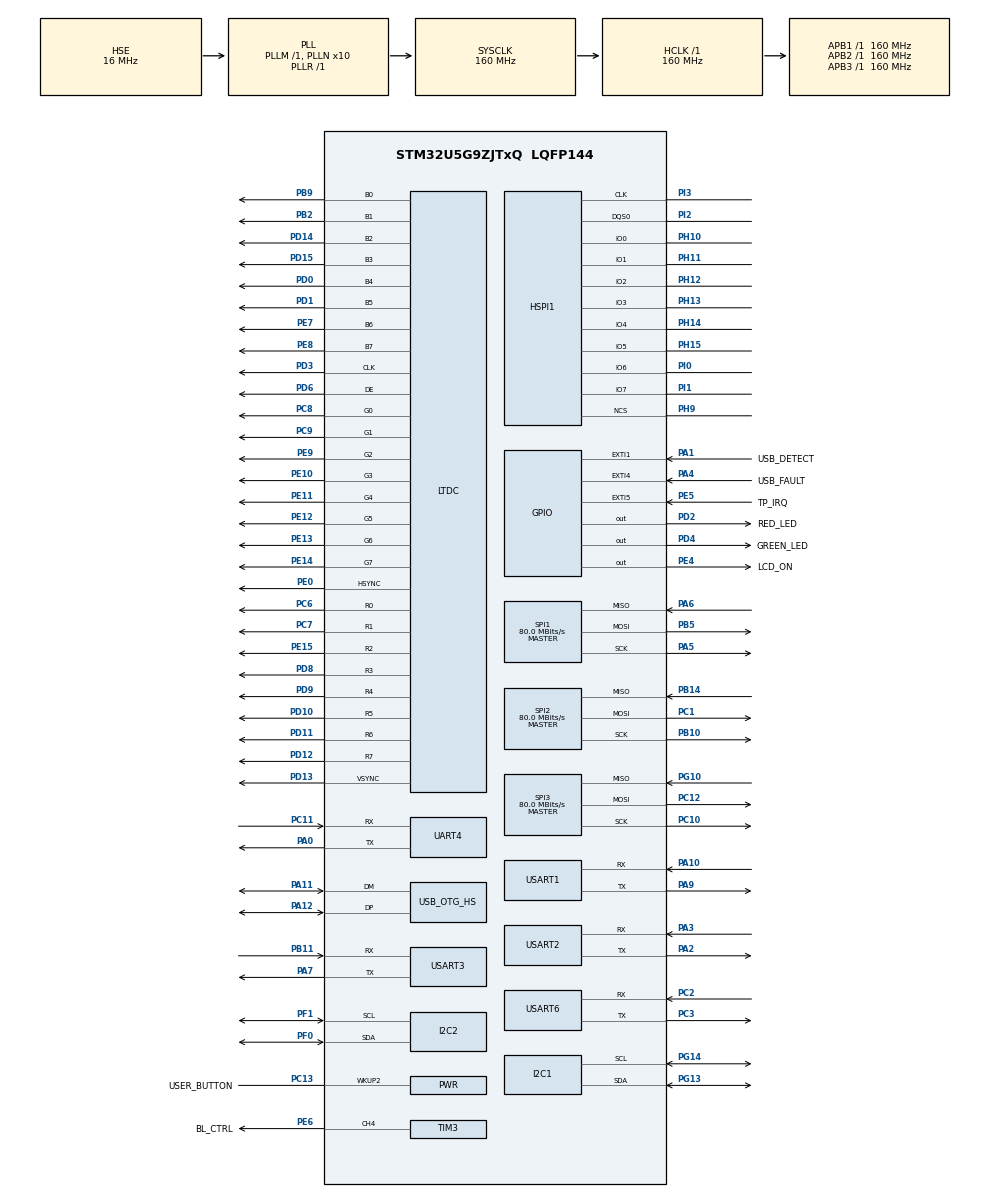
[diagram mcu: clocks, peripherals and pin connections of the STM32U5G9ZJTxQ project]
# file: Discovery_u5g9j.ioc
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ADC1.Channel-0\#ChannelRegularConversion=ADC_CHANNEL_TEMPSENSOR
ADC1.MonitoredBy-0\#ChannelRegularConversion=__NULL
ADC1.NbrOfConversionFlag=1
ADC1.OffsetNumber-0\#ChannelRegularConversion=ADC_OFFSET_NONE
ADC1.Rank-0\#ChannelRegularConversion=1
ADC1.SamplingTime-0\#ChannelRegularConversion=ADC_SAMPLETIME_5CYCLE
ADC1.master=1
CORTEX_M33_NS.userName=CORTEX_M33
DMA2D.ColorMode=DMA2D_OUTPUT_RGB888
DMA2D.Mode=DMA2D_M2M
HSPI1.ChipSelectBoundary=HAL_XSPI_BONDARYOF_NONE
HSPI1.ChipSelectHighTimeCycle=2
HSPI1.FifoThresholdByte=4
HSPI1.MemorySize=HAL_XSPI_SIZE_1GB
HSPI1.MemoryType=HAL_XSPI_MEMTYPE_MACRONIX
I2C1.Timing=0x30909DEC
I2C2.Timing=0x30909DEC
LTDC.ActiveH=480
LTDC.ActiveW=800
LTDC.Alpha_L0=255
LTDC.BlendingFactor1_L0=LTDC_BLENDING_FACTOR1_PAxCA
LTDC.BlendingFactor2_L0=LTDC_BLENDING_FACTOR2_PAxCA
LTDC.HBP=8
LTDC.HFP=8
LTDC.HSync=4
LTDC.Layers=0
LTDC.PCPolarity=LTDC_PCPOLARITY_IPC
LTDC.PixelFormat_L0=LTDC_PIXEL_FORMAT_RGB888
LTDC.VBP=8
LTDC.VFP=8
LTDC.WindowX1_L0=800
LTDC.WindowY1_L0=480
Mcu.Family=STM32U5
Mcu.Name=STM32U5G9ZJTxQ
Mcu.Package=LQFP144
NVIC.EXTI1_IRQn=true\:0\:0\:false\:false\:true\:true\:true\:true
NVIC.EXTI4_IRQn=true\:0\:0\:false\:false\:true\:true\:true\:true
NVIC.EXTI5_IRQn=true\:0\:0\:false\:false\:true\:true\:true\:true
NVIC.I2C2_ER_IRQn=true\:0\:0\:false\:false\:true\:true\:true\:false
NVIC.I2C2_EV_IRQn=true\:0\:0\:false\:false\:true\:true\:true\:true
NVIC.LTDC_IRQn=true\:0\:0\:false\:false\:true\:true\:true\:true
NVIC.PriorityGroup=NVIC_PRIORITYGROUP_4
NVIC.USART1_IRQn=true\:0\:0\:false\:false\:true\:true\:true\:true
PA0.Mode=Asynchronous
PA0.Signal=UART4_TX
PA1.GPIO_Label=USB_DETECT
PA1.GPIO_ModeDefaultEXTI=GPIO_MODE_IT_RISING_FALLING
PA1.Signal=GPXTI1
PA10.Mode=Asynchronous
PA10.Signal=USART1_RX
PA11.Mode=Internal_Phy_Device
PA11.Signal=USB_OTG_HS_DM
PA12.Mode=Internal_Phy_Device
PA12.Signal=USB_OTG_HS_DP
PA13\ (JTMS/SWDIO).Mode=Trace_Asynchronous_SW
PA13\ (JTMS/SWDIO).Signal=DEBUG_JTMS-SWDIO
PA14\ (JTCK/SWCLK).Mode=Trace_Asynchronous_SW
PA14\ (JTCK/SWCLK).Signal=DEBUG_JTCK-SWCLK
PA2.Mode=Asynchronous
PA2.Signal=USART2_TX
PA3.Mode=Asynchronous
PA3.Signal=USART2_RX
PA4.GPIO_Label=USB_FAULT
PA4.GPIO_ModeDefaultEXTI=GPIO_MODE_IT_FALLING
PA4.GPIO_PuPd=GPIO_PULLUP
PA4.Signal=GPXTI4
PA5.Mode=Full_Duplex_Master
PA5.Signal=SPI1_SCK
PA6.Mode=Full_Duplex_Master
PA6.Signal=SPI1_MISO
PA7.Mode=Asynchronous
PA7.Signal=USART3_TX
PA9.Mode=Asynchronous
PA9.Signal=USART1_TX
PB10.Mode=Full_Duplex_Master
PB10.Signal=SPI2_SCK
PB11.Mode=Asynchronous
PB11.Signal=USART3_RX
PB14.Mode=Full_Duplex_Master
PB14.Signal=SPI2_MISO
PB2.Mode=RGB888
PB2.Signal=LTDC_B1
PB3\ (JTDO/TRACESWO).Mode=Trace_Asynchronous_SW
PB3\ (JTDO/TRACESWO).Signal=DEBUG_JTDO-SWO
PB5.Mode=Full_Duplex_Master
PB5.Signal=SPI1_MOSI
PB9.Mode=RGB888
PB9.Signal=LTDC_B0
PC1.Mode=Full_Duplex_Master
PC1.Signal=SPI2_MOSI
PC10.Mode=Full_Duplex_Master
PC10.Signal=SPI3_SCK
PC11.Mode=Asynchronous
PC11.Signal=UART4_RX
PC12.Mode=Full_Duplex_Master
PC12.Signal=SPI3_MOSI
PC13.GPIO_Label=USER_BUTTON
PC13.Mode=WakeUp2
PC13.Signal=PWR_WKUP2
PC14-OSC32_IN\ (PC14).Mode=LSE-External-Oscillator
PC14-OSC32_IN\ (PC14).Signal=RCC_OSC32_IN
PC15-OSC32_OUT\ (PC15).Mode=LSE-External-Oscillator
PC15-OSC32_OUT\ (PC15).Signal=RCC_OSC32_OUT
PC2.Mode=Asynchronous
PC2.Signal=USART6_RX
PC3.Mode=Asynchronous
PC3.Signal=USART6_TX
PC6.Mode=RGB888
PC6.Signal=LTDC_R0
PC7.Mode=RGB888
PC7.Signal=LTDC_R1
PC8.Mode=RGB888
PC8.Signal=LTDC_G0
PC9.Mode=RGB888
PC9.Signal=LTDC_G1
PD0.Mode=RGB888
PD0.Signal=LTDC_B4
PD1.Mode=RGB888
PD1.Signal=LTDC_B5
PD10.Mode=RGB888
PD10.Signal=LTDC_R5
PD11.Mode=RGB888
PD11.Signal=LTDC_R6
PD12.Mode=RGB888
PD12.Signal=LTDC_R7
PD13.Mode=RGB888
PD13.Signal=LTDC_VSYNC
PD14.Mode=RGB888
PD14.Signal=LTDC_B2
PD15.Mode=RGB888
PD15.Signal=LTDC_B3
PD2.GPIO_Label=RED_LED
PD2.Signal=GPIO_Output
PD3.Mode=RGB888
PD3.Signal=LTDC_CLK
PD4.GPIO_Label=GREEN_LED
PD4.Signal=GPIO_Output
PD6.Mode=RGB888
PD6.Signal=LTDC_DE
PD8.Mode=RGB888
PD8.Signal=LTDC_R3
PD9.Mode=RGB888
PD9.Signal=LTDC_R4
PE0.Mode=RGB888
PE0.Signal=LTDC_HSYNC
PE10.Mode=RGB888
PE10.Signal=LTDC_G3
PE11.Mode=RGB888
PE11.Signal=LTDC_G4
PE12.Mode=RGB888
PE12.Signal=LTDC_G5
PE13.Mode=RGB888
PE13.Signal=LTDC_G6
PE14.Mode=RGB888
PE14.Signal=LTDC_G7
PE15.Mode=RGB888
PE15.Signal=LTDC_R2
PE4.GPIO_Label=LCD_ON
PE4.PinState=GPIO_PIN_SET
PE4.Signal=GPIO_Output
PE5.GPIO_Label=TP_IRQ
PE5.Signal=GPXTI5
PE6.GPIO_Label=BL_CTRL
PE6.Signal=S_TIM3_CH4
PE7.Mode=RGB888
PE7.Signal=LTDC_B6
PE8.Mode=RGB888
PE8.Signal=LTDC_B7
PE9.Mode=RGB888
PE9.Signal=LTDC_G2
PF0.Mode=I2C
PF0.Signal=I2C2_SDA
PF1.Mode=I2C
PF1.Signal=I2C2_SCL
PG10.Mode=Full_Duplex_Master
PG10.Signal=SPI3_MISO
PG13.Mode=I2C
PG13.Signal=I2C1_SDA
PG14.Mode=I2C
PG14.Signal=I2C1_SCL
PH0-OSC_IN\ (PH0).Mode=HSE-External-Oscillator
PH0-OSC_IN\ (PH0).Signal=RCC_OSC_IN
PH1-OSC_OUT\ (PH1).Mode=HSE-External-Oscillator
PH1-OSC_OUT\ (PH1).Signal=RCC_OSC_OUT
PH10.Mode=octo_mode
PH10.Signal=HSPI1_IO0
PH11.Mode=octo_mode
PH11.Signal=HSPI1_IO1
PH12.Mode=octo_mode
PH12.Signal=HSPI1_IO2
PH13.Mode=octo_mode
PH13.Signal=HSPI1_IO3
PH14.Mode=octo_mode
PH14.Signal=HSPI1_IO4
PH15.Mode=octo_mode
PH15.Signal=HSPI1_IO5
PH9.Mode=octo_mode
PH9.Signal=HSPI1_NCS
PI0.Mode=octo_mode
PI0.Signal=HSPI1_IO6
PI1.Mode=octo_mode
PI1.Signal=HSPI1_IO7
PI2.Mode=octo_mode
PI2.Signal=HSPI1_DQS0
PI3.Mode=octo_mode
PI3.Signal=HSPI1_CLK
PWR.PowerMode=PWR_SMPS_SUPPLY
ProjectManager.HeapSize=0x200
ProjectManager.StackSize=0x400
ProjectManager.TargetToolchain=STM32CubeIDE
RCC.ADCFreq_Value=16000000
RCC.AHBFreq_Value=160000000
RCC.APB1Freq_Value=160000000
RCC.APB1TimFreq_Value=160000000
RCC.APB2Freq_Value=160000000
RCC.APB2TimFreq_Value=160000000
RCC.APB3Freq_Value=160000000
RCC.CortexFreq_Value=160000000
RCC.EPOD_VALUE=16000000
RCC.HCLKFreq_Value=160000000
RCC.HSE_VALUE=16000000
RCC.HSI48_VALUE=48000000
RCC.HSI_VALUE=16000000
RCC.HSPICLockSelection=RCC_HSPICLKSOURCE_PLL2
RCC.LSIDIV_VALUE=32000
RCC.LTDCCLockSelection=RCC_LTDCCLKSOURCE_PLL3
RCC.MSIClockRange=RCC_MSIRANGE_0
RCC.MSI_VALUE=48000000
RCC.PLL1P=8
RCC.PLL1R=1
RCC.PLL2FRACN=0
RCC.PLL2N=25
RCC.PLL2Q=3
RCC.PLL2R=4
RCC.PLL2Source=RCC_PLLSOURCE_HSE
RCC.PLL3FRACN=0
RCC.PLL3M=4
RCC.PLL3N=50
RCC.PLL3R=8
RCC.PLL3Source=RCC_PLLSOURCE_HSE
RCC.PLLFRACN=0
RCC.PLLN=10
RCC.RTCClockSelection=RCC_RTCCLKSOURCE_LSE
RCC.SYSCLKFreq_VALUE=160000000
RCC.SYSCLKSource=RCC_SYSCLKSOURCE_PLLCLK
RCC.VCOOutputFreq_Value=160000000
SH.S_TIM3_CH4.0=TIM3_CH4,PWM Generation4 CH4
SPI1.CalculateBaudRate=80.0 MBits/s
SPI1.Direction=SPI_DIRECTION_2LINES
SPI1.Mode=SPI_MODE_MASTER
SPI1.VirtualType=VM_MASTER
SPI2.CalculateBaudRate=80.0 MBits/s
SPI2.Direction=SPI_DIRECTION_2LINES
SPI2.Mode=SPI_MODE_MASTER
SPI2.VirtualType=VM_MASTER
SPI3.CalculateBaudRate=80.0 MBits/s
SPI3.Direction=SPI_DIRECTION_2LINES
SPI3.Mode=SPI_MODE_MASTER
SPI3.VirtualType=VM_MASTER
TIM3.Channel-PWM\ Generation4\ CH4=TIM_CHANNEL_4
TIM3.OC4Preload_PWM=DISABLE
TIM3.PeriodNoDither=100
TIM3.Prescaler=160
TIM3.PulseNoDither_4=75
USART1.VirtualMode-Asynchronous=VM_ASYNC
USART2.VirtualMode-Asynchronous=VM_ASYNC
USART3.VirtualMode-Asynchronous=VM_ASYNC
USART6.VirtualMode-Asynchronous=VM_ASYNC
USB_OTG_HS.VirtualMode=Device_HS
VP_ADC1_TempSens_Input.Mode=IN-TempSens
VP_DMA2D_VS_DMA2D.Mode=DMA2D_Activate
VP_ICACHE_VS_ICACHE.Mode=DirectMappedCache
VP_LPBAMQUEUE_VS_QUEUE.Mode=QUEUEMODE
VP_MEMORYMAP_VS_MEMORYMAP.Mode=CurAppReg
VP_PWR_VS_LPOM.Mode=PowerOptimisation
VP_PWR_VS_SECSignals.Mode=Security/Privilege
VP_PWR_Vdda.Mode=isolationVdda
VP_RTC_VS_RTC_Activate.Mode=RTC_Enabled
board=STM32U5G9J-DK2

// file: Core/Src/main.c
/* USER CODE BEGIN Header */
/**
  ******************************************************************************
  * @file           : main.c
  * @brief          : Main program body
  ******************************************************************************
  * @attention
  *
  * Copyright (c) 2026 STMicroelectronics.
  * All rights reserved.
  *
  * This software is licensed under terms that can be found in the LICENSE file
  * in the root directory of this software component.
  * If no LICENSE file comes with this software, it is provided AS-IS.
  *
  ******************************************************************************
  */
/* USER CODE END Header */
#include "main.h"
#include "FreeRTOS.h"   /* V6/A1.5: el kernel */
#include "task.h"

/* USER CODE BEGIN Includes */
#include "stm32_repl.h"
/* USER CODE END Includes */

ADC_HandleTypeDef hadc1;

DMA2D_HandleTypeDef hdma2d;

XSPI_HandleTypeDef hxspi1;

I2C_HandleTypeDef hi2c1;
I2C_HandleTypeDef hi2c2;

LTDC_HandleTypeDef hltdc;

RTC_HandleTypeDef hrtc;

SPI_HandleTypeDef hspi1;
SPI_HandleTypeDef hspi2;
SPI_HandleTypeDef hspi3;

TIM_HandleTypeDef htim3;

UART_HandleTypeDef huart4;
UART_HandleTypeDef huart1;
UART_HandleTypeDef huart2;
UART_HandleTypeDef huart3;
UART_HandleTypeDef huart6;

PCD_HandleTypeDef hpcd_USB_OTG_HS;

void SystemClock_Config(void);
static void SystemPower_Config(void);
static void MX_GPIO_Init(void);
static void MX_DMA2D_Init(void);
static void MX_HSPI1_Init(void);
static void MX_I2C1_Init(void);
static void MX_I2C2_Init(void);
static void MX_ICACHE_Init(void);
static void MX_LTDC_Init(void);
static void MX_RTC_Init(void);
static void MX_SPI1_Init(void);
static void MX_SPI2_Init(void);
static void MX_SPI3_Init(void);
static void MX_TIM3_Init(void);
static void MX_UART4_Init(void);
static void MX_USART1_UART_Init(void);
static void MX_USART2_UART_Init(void);
static void MX_USART3_UART_Init(void);
static void MX_USART6_UART_Init(void);
static void MX_USB_OTG_HS_PCD_Init(void);
static void MX_ADC1_Init(void);

/* V6/A1.5 - la tarea `vm`: lo de siempre, sobre su pila y bajo el planificador. */
static void vm_task(void* arg)
{
  (void) arg;
  for (;;) { stm32_repl_run(); }
}

int main(void)
{

  /* MCU Configuration--------------------------------------------------------*/

  /* Reset of all peripherals, Initializes the Flash interface and the Systick. */
  HAL_Init();

  /* Configure the System Power */
  SystemPower_Config();

  /* Configure the system clock */
  SystemClock_Config();

  /* Initialize all configured peripherals */
  MX_GPIO_Init();
  MX_DMA2D_Init();
  MX_HSPI1_Init();
  MX_I2C1_Init();
  MX_I2C2_Init();
  MX_ICACHE_Init();
  MX_LTDC_Init();
  MX_RTC_Init();
  MX_SPI1_Init();
  MX_SPI2_Init();
  MX_SPI3_Init();
  MX_TIM3_Init();
  MX_UART4_Init();
  MX_USART1_UART_Init();
  MX_USART2_UART_Init();
  MX_USART3_UART_Init();
  MX_USART6_UART_Init();
  MX_USB_OTG_HS_PCD_Init();
  MX_ADC1_Init();

  /* Infinite loop */
  /* USER CODE BEGIN WHILE */
  /* V6/A1.5 - LAS DOS TAREAS (ver el gemelo en Nucleo_u575b/Core/Src/main.c).
   * La pila de `vm`, 4096 PALABRAS = 16 KB: el mismo _Min_Stack_Size que el
   * enlazador reservaba como MSP para que el interprete corriera encima. */
  if (xTaskCreate(vm_task, "vm", 4096, NULL, tskIDLE_PRIORITY + 2, NULL) != pdPASS) {
    Error_Handler();
  }
  vTaskStartScheduler();
  Error_Handler();   /* solo se llega aqui si el planificador no arranco */
  while (1) { }
  /* USER CODE END 3 */
}

void SystemClock_Config(void)
{
  RCC_OscInitTypeDef RCC_OscInitStruct = {0};
  RCC_ClkInitTypeDef RCC_ClkInitStruct = {0};

  /** Configure the main internal regulator output voltage
  */
  if (HAL_PWREx_ControlVoltageScaling(PWR_REGULATOR_VOLTAGE_SCALE1) != HAL_OK)
  {
    Error_Handler();
  }

  /** Configure LSE Drive Capability
  */
  HAL_PWR_EnableBkUpAccess();
  __HAL_RCC_LSEDRIVE_CONFIG(RCC_LSEDRIVE_LOW);

  /** Initializes the CPU, AHB and APB buses clocks
  */
  RCC_OscInitStruct.OscillatorType = RCC_OSCILLATORTYPE_HSI|RCC_OSCILLATORTYPE_HSE
                              |RCC_OSCILLATORTYPE_LSE|RCC_OSCILLATORTYPE_MSI;
  RCC_OscInitStruct.HSEState = RCC_HSE_ON;
  RCC_OscInitStruct.LSEState = RCC_LSE_ON;
  RCC_OscInitStruct.HSIState = RCC_HSI_ON;
  RCC_OscInitStruct.HSICalibrationValue = RCC_HSICALIBRATION_DEFAULT;
  RCC_OscInitStruct.MSIState = RCC_MSI_ON;
  RCC_OscInitStruct.MSICalibrationValue = RCC_MSICALIBRATION_DEFAULT;
  RCC_OscInitStruct.MSIClockRange = RCC_MSIRANGE_0;
  RCC_OscInitStruct.PLL.PLLState = RCC_PLL_ON;
  RCC_OscInitStruct.PLL.PLLSource = RCC_PLLSOURCE_HSE;
  RCC_OscInitStruct.PLL.PLLMBOOST = RCC_PLLMBOOST_DIV1;
  RCC_OscInitStruct.PLL.PLLM = 1;
  RCC_OscInitStruct.PLL.PLLN = 10;
  RCC_OscInitStruct.PLL.PLLP = 8;
  RCC_OscInitStruct.PLL.PLLQ = 2;
  RCC_OscInitStruct.PLL.PLLR = 1;
  RCC_OscInitStruct.PLL.PLLRGE = RCC_PLLVCIRANGE_1;
  RCC_OscInitStruct.PLL.PLLFRACN = 0;
  if (HAL_RCC_OscConfig(&RCC_OscInitStruct) != HAL_OK)
  {
    Error_Handler();
  }

  /** Initializes the CPU, AHB and APB buses clocks
  */
  RCC_ClkInitStruct.ClockType = RCC_CLOCKTYPE_HCLK|RCC_CLOCKTYPE_SYSCLK
                              |RCC_CLOCKTYPE_PCLK1|RCC_CLOCKTYPE_PCLK2
                              |RCC_CLOCKTYPE_PCLK3;
  RCC_ClkInitStruct.SYSCLKSource = RCC_SYSCLKSOURCE_PLLCLK;
  RCC_ClkInitStruct.AHBCLKDivider = RCC_SYSCLK_DIV1;
  RCC_ClkInitStruct.APB1CLKDivider = RCC_HCLK_DIV1;
  RCC_ClkInitStruct.APB2CLKDivider = RCC_HCLK_DIV1;
  RCC_ClkInitStruct.APB3CLKDivider = RCC_HCLK_DIV1;

  if (HAL_RCC_ClockConfig(&RCC_ClkInitStruct, FLASH_LATENCY_4) != HAL_OK)
  {
    Error_Handler();
  }
}

/**
  * @brief Power Configuration
  * @retval None
  */
static void SystemPower_Config(void)
{
  HAL_PWREx_EnableVddIO2();

  /*
   * Switch to SMPS regulator instead of LDO
   */
  if (HAL_PWREx_ConfigSupply(PWR_SMPS_SUPPLY) != HAL_OK)
  {
    Error_Handler();
  }
}

static void MX_ADC1_Init(void)
{

  ADC_ChannelConfTypeDef sConfig = {0};

  /** Common config
  */
  hadc1.Instance = ADC1;
  hadc1.Init.ClockPrescaler = ADC_CLOCK_ASYNC_DIV1;
  hadc1.Init.Resolution = ADC_RESOLUTION_14B;
  hadc1.Init.GainCompensation = 0;
  hadc1.Init.DataAlign = ADC_DATAALIGN_RIGHT;
  hadc1.Init.ScanConvMode = ADC_SCAN_DISABLE;
  hadc1.Init.EOCSelection = ADC_EOC_SINGLE_CONV;
  hadc1.Init.LowPowerAutoWait = DISABLE;
  hadc1.Init.ContinuousConvMode = DISABLE;
  hadc1.Init.NbrOfConversion = 1;
  hadc1.Init.DiscontinuousConvMode = DISABLE;
  hadc1.Init.ExternalTrigConv = ADC_SOFTWARE_START;
  hadc1.Init.ExternalTrigConvEdge = ADC_EXTERNALTRIGCONVEDGE_NONE;
  hadc1.Init.DMAContinuousRequests = DISABLE;
  hadc1.Init.TriggerFrequencyMode = ADC_TRIGGER_FREQ_HIGH;
  hadc1.Init.Overrun = ADC_OVR_DATA_PRESERVED;
  hadc1.Init.LeftBitShift = ADC_LEFTBITSHIFT_NONE;
  hadc1.Init.ConversionDataManagement = ADC_CONVERSIONDATA_DR;
  hadc1.Init.OversamplingMode = DISABLE;
  if (HAL_ADC_Init(&hadc1) != HAL_OK)
  {
    Error_Handler();
  }

  /** Configure Regular Channel
  */
  sConfig.Channel = ADC_CHANNEL_TEMPSENSOR;
  sConfig.Rank = ADC_REGULAR_RANK_1;
  sConfig.SamplingTime = ADC_SAMPLETIME_5CYCLE;
  sConfig.SingleDiff = ADC_SINGLE_ENDED;
  sConfig.OffsetNumber = ADC_OFFSET_NONE;
  sConfig.Offset = 0;
  if (HAL_ADC_ConfigChannel(&hadc1, &sConfig) != HAL_OK)
  {
    Error_Handler();
  }

}

static void MX_DMA2D_Init(void)
{

  hdma2d.Instance = DMA2D;
  hdma2d.Init.Mode = DMA2D_M2M;
  hdma2d.Init.ColorMode = DMA2D_OUTPUT_RGB888;
  hdma2d.Init.OutputOffset = 0;
  hdma2d.Init.BytesSwap = DMA2D_BYTES_REGULAR;
  hdma2d.Init.LineOffsetMode = DMA2D_LOM_PIXELS;
  hdma2d.LayerCfg[1].InputOffset = 0;
  hdma2d.LayerCfg[1].InputColorMode = DMA2D_INPUT_RGB888;
  hdma2d.LayerCfg[1].AlphaMode = DMA2D_NO_MODIF_ALPHA;
  hdma2d.LayerCfg[1].InputAlpha = 0;
  hdma2d.LayerCfg[1].AlphaInverted = DMA2D_REGULAR_ALPHA;
  hdma2d.LayerCfg[1].RedBlueSwap = DMA2D_RB_REGULAR;
  if (HAL_DMA2D_Init(&hdma2d) != HAL_OK)
  {
    Error_Handler();
  }
  if (HAL_DMA2D_ConfigLayer(&hdma2d, 1) != HAL_OK)
  {
    Error_Handler();
  }

}

static void MX_HSPI1_Init(void)
{

  /* HSPI1 parameter configuration*/
  hxspi1.Instance = HSPI1;
  hxspi1.Init.FifoThresholdByte = 4;
  hxspi1.Init.MemoryMode = HAL_XSPI_SINGLE_MEM;
  hxspi1.Init.MemoryType = HAL_XSPI_MEMTYPE_MACRONIX;
  hxspi1.Init.MemorySize = HAL_XSPI_SIZE_1GB;
  hxspi1.Init.ChipSelectHighTimeCycle = 2;
  hxspi1.Init.FreeRunningClock = HAL_XSPI_FREERUNCLK_DISABLE;
  hxspi1.Init.ClockMode = HAL_XSPI_CLOCK_MODE_0;
  hxspi1.Init.WrapSize = HAL_XSPI_WRAP_NOT_SUPPORTED;
  hxspi1.Init.ClockPrescaler = 0;
  hxspi1.Init.SampleShifting = HAL_XSPI_SAMPLE_SHIFT_NONE;
  hxspi1.Init.DelayHoldQuarterCycle = HAL_XSPI_DHQC_DISABLE;
  hxspi1.Init.ChipSelectBoundary = HAL_XSPI_BONDARYOF_NONE;
  hxspi1.Init.MaxTran = 0;
  hxspi1.Init.Refresh = 0;
  if (HAL_XSPI_Init(&hxspi1) != HAL_OK)
  {
    Error_Handler();
  }

}

static void MX_I2C1_Init(void)
{

  hi2c1.Instance = I2C1;
  hi2c1.Init.Timing = 0x30909DEC;
  hi2c1.Init.OwnAddress1 = 0;
  hi2c1.Init.AddressingMode = I2C_ADDRESSINGMODE_7BIT;
  hi2c1.Init.DualAddressMode = I2C_DUALADDRESS_DISABLE;
  hi2c1.Init.OwnAddress2 = 0;
  hi2c1.Init.OwnAddress2Masks = I2C_OA2_NOMASK;
  hi2c1.Init.GeneralCallMode = I2C_GENERALCALL_DISABLE;
  hi2c1.Init.NoStretchMode = I2C_NOSTRETCH_DISABLE;
  if (HAL_I2C_Init(&hi2c1) != HAL_OK)
  {
    Error_Handler();
  }

  /** Configure Analogue filter
  */
  if (HAL_I2CEx_ConfigAnalogFilter(&hi2c1, I2C_ANALOGFILTER_ENABLE) != HAL_OK)
  {
    Error_Handler();
  }

  /** Configure Digital filter
  */
  if (HAL_I2CEx_ConfigDigitalFilter(&hi2c1, 0) != HAL_OK)
  {
    Error_Handler();
  }

}

static void MX_I2C2_Init(void)
{

  hi2c2.Instance = I2C2;
  hi2c2.Init.Timing = 0x30909DEC;
  hi2c2.Init.OwnAddress1 = 0;
  hi2c2.Init.AddressingMode = I2C_ADDRESSINGMODE_7BIT;
  hi2c2.Init.DualAddressMode = I2C_DUALADDRESS_DISABLE;
  hi2c2.Init.OwnAddress2 = 0;
  hi2c2.Init.OwnAddress2Masks = I2C_OA2_NOMASK;
  hi2c2.Init.GeneralCallMode = I2C_GENERALCALL_DISABLE;
  hi2c2.Init.NoStretchMode = I2C_NOSTRETCH_DISABLE;
  if (HAL_I2C_Init(&hi2c2) != HAL_OK)
  {
    Error_Handler();
  }

  /** Configure Analogue filter
  */
  if (HAL_I2CEx_ConfigAnalogFilter(&hi2c2, I2C_ANALOGFILTER_ENABLE) != HAL_OK)
  {
    Error_Handler();
  }

  /** Configure Digital filter
  */
  if (HAL_I2CEx_ConfigDigitalFilter(&hi2c2, 0) != HAL_OK)
  {
    Error_Handler();
  }

}

static void MX_ICACHE_Init(void)
{

  /** Enable instruction cache in 1-way (direct mapped cache)
  */
  if (HAL_ICACHE_ConfigAssociativityMode(ICACHE_1WAY) != HAL_OK)
  {
    Error_Handler();
  }
  if (HAL_ICACHE_Enable() != HAL_OK)
  {
    Error_Handler();
  }

}

static void MX_LTDC_Init(void)
{

  LTDC_LayerCfgTypeDef pLayerCfg = {0};

  hltdc.Instance = LTDC;
  hltdc.Init.HSPolarity = LTDC_HSPOLARITY_AL;
  hltdc.Init.VSPolarity = LTDC_VSPOLARITY_AL;
  hltdc.Init.DEPolarity = LTDC_DEPOLARITY_AL;
  hltdc.Init.PCPolarity = LTDC_PCPOLARITY_IPC;
  hltdc.Init.HorizontalSync = 3;
  hltdc.Init.VerticalSync = 3;
  hltdc.Init.AccumulatedHBP = 11;
  hltdc.Init.AccumulatedVBP = 11;
  hltdc.Init.AccumulatedActiveW = 811;
  hltdc.Init.AccumulatedActiveH = 491;
  hltdc.Init.TotalWidth = 819;
  hltdc.Init.TotalHeigh = 499;
  hltdc.Init.Backcolor.Blue = 0;
  hltdc.Init.Backcolor.Green = 0;
  hltdc.Init.Backcolor.Red = 0;
  if (HAL_LTDC_Init(&hltdc) != HAL_OK)
  {
    Error_Handler();
  }
  pLayerCfg.WindowX0 = 0;
  pLayerCfg.WindowX1 = 800;
  pLayerCfg.WindowY0 = 0;
  pLayerCfg.WindowY1 = 480;
  pLayerCfg.PixelFormat = LTDC_PIXEL_FORMAT_RGB888;
  pLayerCfg.Alpha = 255;
  pLayerCfg.Alpha0 = 0;
  pLayerCfg.BlendingFactor1 = LTDC_BLENDING_FACTOR1_PAxCA;
  pLayerCfg.BlendingFactor2 = LTDC_BLENDING_FACTOR2_PAxCA;
  pLayerCfg.FBStartAdress = 0;
  pLayerCfg.ImageWidth = 0;
  pLayerCfg.ImageHeight = 0;
  pLayerCfg.Backcolor.Blue = 0;
  pLayerCfg.Backcolor.Green = 0;
  pLayerCfg.Backcolor.Red = 0;
  if (HAL_LTDC_ConfigLayer(&hltdc, &pLayerCfg, 0) != HAL_OK)
  {
    Error_Handler();
  }

}

static void MX_RTC_Init(void)
{

  RTC_PrivilegeStateTypeDef privilegeState = {0};

  /** Initialize RTC Only
  */
  hrtc.Instance = RTC;
  hrtc.Init.HourFormat = RTC_HOURFORMAT_24;
  hrtc.Init.AsynchPrediv = 127;
  hrtc.Init.SynchPrediv = 255;
  hrtc.Init.OutPut = RTC_OUTPUT_DISABLE;
  hrtc.Init.OutPutRemap = RTC_OUTPUT_REMAP_NONE;
  hrtc.Init.OutPutPolarity = RTC_OUTPUT_POLARITY_HIGH;
  hrtc.Init.OutPutType = RTC_OUTPUT_TYPE_OPENDRAIN;
  hrtc.Init.OutPutPullUp = RTC_OUTPUT_PULLUP_NONE;
  hrtc.Init.BinMode = RTC_BINARY_NONE;
  if (HAL_RTC_Init(&hrtc) != HAL_OK)
  {
    Error_Handler();
  }
  privilegeState.rtcPrivilegeFull = RTC_PRIVILEGE_FULL_NO;
  privilegeState.backupRegisterPrivZone = RTC_PRIVILEGE_BKUP_ZONE_NONE;
  privilegeState.backupRegisterStartZone2 = RTC_BKP_DR0;
  privilegeState.backupRegisterStartZone3 = RTC_BKP_DR0;
  if (HAL_RTCEx_PrivilegeModeSet(&hrtc, &privilegeState) != HAL_OK)
  {
    Error_Handler();
  }

}

static void MX_SPI1_Init(void)
{

  SPI_AutonomousModeConfTypeDef HAL_SPI_AutonomousMode_Cfg_Struct = {0};

  /* SPI1 parameter configuration*/
  hspi1.Instance = SPI1;
  hspi1.Init.Mode = SPI_MODE_MASTER;
  hspi1.Init.Direction = SPI_DIRECTION_2LINES;
  hspi1.Init.DataSize = SPI_DATASIZE_4BIT;
  hspi1.Init.CLKPolarity = SPI_POLARITY_LOW;
  hspi1.Init.CLKPhase = SPI_PHASE_1EDGE;
  hspi1.Init.NSS = SPI_NSS_SOFT;
  hspi1.Init.BaudRatePrescaler = SPI_BAUDRATEPRESCALER_2;
  hspi1.Init.FirstBit = SPI_FIRSTBIT_MSB;
  hspi1.Init.TIMode = SPI_TIMODE_DISABLE;
  hspi1.Init.CRCCalculation = SPI_CRCCALCULATION_DISABLE;
  hspi1.Init.CRCPolynomial = 0x7;
  hspi1.Init.NSSPMode = SPI_NSS_PULSE_ENABLE;
  hspi1.Init.NSSPolarity = SPI_NSS_POLARITY_LOW;
  hspi1.Init.FifoThreshold = SPI_FIFO_THRESHOLD_01DATA;
  hspi1.Init.MasterSSIdleness = SPI_MASTER_SS_IDLENESS_00CYCLE;
  hspi1.Init.MasterInterDataIdleness = SPI_MASTER_INTERDATA_IDLENESS_00CYCLE;
  hspi1.Init.MasterReceiverAutoSusp = SPI_MASTER_RX_AUTOSUSP_DISABLE;
  hspi1.Init.MasterKeepIOState = SPI_MASTER_KEEP_IO_STATE_DISABLE;
  hspi1.Init.IOSwap = SPI_IO_SWAP_DISABLE;
  hspi1.Init.ReadyMasterManagement = SPI_RDY_MASTER_MANAGEMENT_INTERNALLY;
  hspi1.Init.ReadyPolarity = SPI_RDY_POLARITY_HIGH;
  if (HAL_SPI_Init(&hspi1) != HAL_OK)
  {
    Error_Handler();
  }
  HAL_SPI_AutonomousMode_Cfg_Struct.TriggerState = SPI_AUTO_MODE_DISABLE;
  HAL_SPI_AutonomousMode_Cfg_Struct.TriggerSelection = SPI_GRP1_GPDMA_CH0_TCF_TRG;
  HAL_SPI_AutonomousMode_Cfg_Struct.TriggerPolarity = SPI_TRIG_POLARITY_RISING;
  if (HAL_SPIEx_SetConfigAutonomousMode(&hspi1, &HAL_SPI_AutonomousMode_Cfg_Struct) != HAL_OK)
  {
    Error_Handler();
  }

}

static void MX_SPI2_Init(void)
{

  SPI_AutonomousModeConfTypeDef HAL_SPI_AutonomousMode_Cfg_Struct = {0};

  /* SPI2 parameter configuration*/
  hspi2.Instance = SPI2;
  hspi2.Init.Mode = SPI_MODE_MASTER;
  hspi2.Init.Direction = SPI_DIRECTION_2LINES;
  hspi2.Init.DataSize = SPI_DATASIZE_4BIT;
  hspi2.Init.CLKPolarity = SPI_POLARITY_LOW;
  hspi2.Init.CLKPhase = SPI_PHASE_1EDGE;
  hspi2.Init.NSS = SPI_NSS_SOFT;
  hspi2.Init.BaudRatePrescaler = SPI_BAUDRATEPRESCALER_2;
  hspi2.Init.FirstBit = SPI_FIRSTBIT_MSB;
  hspi2.Init.TIMode = SPI_TIMODE_DISABLE;
  hspi2.Init.CRCCalculation = SPI_CRCCALCULATION_DISABLE;
  hspi2.Init.CRCPolynomial = 0x7;
  hspi2.Init.NSSPMode = SPI_NSS_PULSE_ENABLE;
  hspi2.Init.NSSPolarity = SPI_NSS_POLARITY_LOW;
  hspi2.Init.FifoThreshold = SPI_FIFO_THRESHOLD_01DATA;
  hspi2.Init.MasterSSIdleness = SPI_MASTER_SS_IDLENESS_00CYCLE;
  hspi2.Init.MasterInterDataIdleness = SPI_MASTER_INTERDATA_IDLENESS_00CYCLE;
  hspi2.Init.MasterReceiverAutoSusp = SPI_MASTER_RX_AUTOSUSP_DISABLE;
  hspi2.Init.MasterKeepIOState = SPI_MASTER_KEEP_IO_STATE_DISABLE;
  hspi2.Init.IOSwap = SPI_IO_SWAP_DISABLE;
  hspi2.Init.ReadyMasterManagement = SPI_RDY_MASTER_MANAGEMENT_INTERNALLY;
  hspi2.Init.ReadyPolarity = SPI_RDY_POLARITY_HIGH;
  if (HAL_SPI_Init(&hspi2) != HAL_OK)
  {
    Error_Handler();
  }
  HAL_SPI_AutonomousMode_Cfg_Struct.TriggerState = SPI_AUTO_MODE_DISABLE;
  HAL_SPI_AutonomousMode_Cfg_Struct.TriggerSelection = SPI_GRP1_GPDMA_CH0_TCF_TRG;
  HAL_SPI_AutonomousMode_Cfg_Struct.TriggerPolarity = SPI_TRIG_POLARITY_RISING;
  if (HAL_SPIEx_SetConfigAutonomousMode(&hspi2, &HAL_SPI_AutonomousMode_Cfg_Struct) != HAL_OK)
  {
    Error_Handler();
  }

}

static void MX_SPI3_Init(void)
{

  SPI_AutonomousModeConfTypeDef HAL_SPI_AutonomousMode_Cfg_Struct = {0};

  /* SPI3 parameter configuration*/
  hspi3.Instance = SPI3;
  hspi3.Init.Mode = SPI_MODE_MASTER;
  hspi3.Init.Direction = SPI_DIRECTION_2LINES;
  hspi3.Init.DataSize = SPI_DATASIZE_8BIT;
  hspi3.Init.CLKPolarity = SPI_POLARITY_LOW;
  hspi3.Init.CLKPhase = SPI_PHASE_1EDGE;
  hspi3.Init.NSS = SPI_NSS_SOFT;
  hspi3.Init.BaudRatePrescaler = SPI_BAUDRATEPRESCALER_2;
  hspi3.Init.FirstBit = SPI_FIRSTBIT_MSB;
  hspi3.Init.TIMode = SPI_TIMODE_DISABLE;
  hspi3.Init.CRCCalculation = SPI_CRCCALCULATION_DISABLE;
  hspi3.Init.CRCPolynomial = 0x7;
  hspi3.Init.NSSPMode = SPI_NSS_PULSE_ENABLE;
  hspi3.Init.NSSPolarity = SPI_NSS_POLARITY_LOW;
  hspi3.Init.FifoThreshold = SPI_FIFO_THRESHOLD_01DATA;
  hspi3.Init.MasterSSIdleness = SPI_MASTER_SS_IDLENESS_00CYCLE;
  hspi3.Init.MasterInterDataIdleness = SPI_MASTER_INTERDATA_IDLENESS_00CYCLE;
  hspi3.Init.MasterReceiverAutoSusp = SPI_MASTER_RX_AUTOSUSP_DISABLE;
  hspi3.Init.MasterKeepIOState = SPI_MASTER_KEEP_IO_STATE_DISABLE;
  hspi3.Init.IOSwap = SPI_IO_SWAP_DISABLE;
  hspi3.Init.ReadyMasterManagement = SPI_RDY_MASTER_MANAGEMENT_INTERNALLY;
  hspi3.Init.ReadyPolarity = SPI_RDY_POLARITY_HIGH;
  if (HAL_SPI_Init(&hspi3) != HAL_OK)
  {
    Error_Handler();
  }
  HAL_SPI_AutonomousMode_Cfg_Struct.TriggerState = SPI_AUTO_MODE_DISABLE;
  HAL_SPI_AutonomousMode_Cfg_Struct.TriggerSelection = SPI_GRP2_LPDMA_CH0_TCF_TRG;
  HAL_SPI_AutonomousMode_Cfg_Struct.TriggerPolarity = SPI_TRIG_POLARITY_RISING;
  if (HAL_SPIEx_SetConfigAutonomousMode(&hspi3, &HAL_SPI_AutonomousMode_Cfg_Struct) != HAL_OK)
  {
    Error_Handler();
  }

}

static void MX_TIM3_Init(void)
{

  TIM_MasterConfigTypeDef sMasterConfig = {0};
  TIM_OC_InitTypeDef sConfigOC = {0};

  htim3.Instance = TIM3;
  htim3.Init.Prescaler = 160;
  htim3.Init.CounterMode = TIM_COUNTERMODE_UP;
  htim3.Init.Period = 100;
  htim3.Init.ClockDivision = TIM_CLOCKDIVISION_DIV1;
  htim3.Init.AutoReloadPreload = TIM_AUTORELOAD_PRELOAD_DISABLE;
  if (HAL_TIM_PWM_Init(&htim3) != HAL_OK)
  {
    Error_Handler();
  }
  sMasterConfig.MasterOutputTrigger = TIM_TRGO_RESET;
  sMasterConfig.MasterSlaveMode = TIM_MASTERSLAVEMODE_DISABLE;
  if (HAL_TIMEx_MasterConfigSynchronization(&htim3, &sMasterConfig) != HAL_OK)
  {
    Error_Handler();
  }
  sConfigOC.OCMode = TIM_OCMODE_PWM1;
  sConfigOC.Pulse = 75;
  sConfigOC.OCPolarity = TIM_OCPOLARITY_HIGH;
  sConfigOC.OCFastMode = TIM_OCFAST_DISABLE;
  if (HAL_TIM_PWM_ConfigChannel(&htim3, &sConfigOC, TIM_CHANNEL_4) != HAL_OK)
  {
    Error_Handler();
  }
  __HAL_TIM_DISABLE_OCxPRELOAD(&htim3, TIM_CHANNEL_4);
  HAL_TIM_MspPostInit(&htim3);

}

static void MX_UART4_Init(void)
{

  huart4.Instance = UART4;
  huart4.Init.BaudRate = 115200;
  huart4.Init.WordLength = UART_WORDLENGTH_8B;
  huart4.Init.StopBits = UART_STOPBITS_1;
  huart4.Init.Parity = UART_PARITY_NONE;
  huart4.Init.Mode = UART_MODE_TX_RX;
  huart4.Init.HwFlowCtl = UART_HWCONTROL_NONE;
  huart4.Init.OverSampling = UART_OVERSAMPLING_16;
  huart4.Init.OneBitSampling = UART_ONE_BIT_SAMPLE_DISABLE;
  huart4.Init.ClockPrescaler = UART_PRESCALER_DIV1;
  huart4.AdvancedInit.AdvFeatureInit = UART_ADVFEATURE_NO_INIT;
  if (HAL_UART_Init(&huart4) != HAL_OK)
  {
    Error_Handler();
  }
  if (HAL_UARTEx_SetTxFifoThreshold(&huart4, UART_TXFIFO_THRESHOLD_1_8) != HAL_OK)
  {
    Error_Handler();
  }
  if (HAL_UARTEx_SetRxFifoThreshold(&huart4, UART_RXFIFO_THRESHOLD_1_8) != HAL_OK)
  {
    Error_Handler();
  }
  if (HAL_UARTEx_DisableFifoMode(&huart4) != HAL_OK)
  {
    Error_Handler();
  }

}

static void MX_USART1_UART_Init(void)
{

  huart1.Instance = USART1;
  huart1.Init.BaudRate = 115200;
  huart1.Init.WordLength = UART_WORDLENGTH_8B;
  huart1.Init.StopBits = UART_STOPBITS_1;
  huart1.Init.Parity = UART_PARITY_NONE;
  huart1.Init.Mode = UART_MODE_TX_RX;
  huart1.Init.HwFlowCtl = UART_HWCONTROL_NONE;
  huart1.Init.OverSampling = UART_OVERSAMPLING_16;
  huart1.Init.OneBitSampling = UART_ONE_BIT_SAMPLE_DISABLE;
  huart1.Init.ClockPrescaler = UART_PRESCALER_DIV1;
  huart1.AdvancedInit.AdvFeatureInit = UART_ADVFEATURE_NO_INIT;
  if (HAL_UART_Init(&huart1) != HAL_OK)
  {
    Error_Handler();
  }
  if (HAL_UARTEx_SetTxFifoThreshold(&huart1, UART_TXFIFO_THRESHOLD_1_8) != HAL_OK)
  {
    Error_Handler();
  }
  if (HAL_UARTEx_SetRxFifoThreshold(&huart1, UART_RXFIFO_THRESHOLD_1_8) != HAL_OK)
  {
    Error_Handler();
  }
  if (HAL_UARTEx_DisableFifoMode(&huart1) != HAL_OK)
  {
    Error_Handler();
  }

}

static void MX_USART2_UART_Init(void)
{

  huart2.Instance = USART2;
  huart2.Init.BaudRate = 115200;
  huart2.Init.WordLength = UART_WORDLENGTH_8B;
  huart2.Init.StopBits = UART_STOPBITS_1;
  huart2.Init.Parity = UART_PARITY_NONE;
  huart2.Init.Mode = UART_MODE_TX_RX;
  huart2.Init.HwFlowCtl = UART_HWCONTROL_NONE;
  huart2.Init.OverSampling = UART_OVERSAMPLING_16;
  huart2.Init.OneBitSampling = UART_ONE_BIT_SAMPLE_DISABLE;
  huart2.Init.ClockPrescaler = UART_PRESCALER_DIV1;
  huart2.AdvancedInit.AdvFeatureInit = UART_ADVFEATURE_NO_INIT;
  if (HAL_UART_Init(&huart2) != HAL_OK)
  {
    Error_Handler();
  }
  if (HAL_UARTEx_SetTxFifoThreshold(&huart2, UART_TXFIFO_THRESHOLD_1_8) != HAL_OK)
  {
    Error_Handler();
  }
  if (HAL_UARTEx_SetRxFifoThreshold(&huart2, UART_RXFIFO_THRESHOLD_1_8) != HAL_OK)
  {
    Error_Handler();
  }
  if (HAL_UARTEx_DisableFifoMode(&huart2) != HAL_OK)
  {
    Error_Handler();
  }

}

static void MX_USART3_UART_Init(void)
{

  huart3.Instance = USART3;
  huart3.Init.BaudRate = 115200;
  huart3.Init.WordLength = UART_WORDLENGTH_8B;
  huart3.Init.StopBits = UART_STOPBITS_1;
  huart3.Init.Parity = UART_PARITY_NONE;
  huart3.Init.Mode = UART_MODE_TX_RX;
  huart3.Init.HwFlowCtl = UART_HWCONTROL_NONE;
  huart3.Init.OverSampling = UART_OVERSAMPLING_16;
  huart3.Init.OneBitSampling = UART_ONE_BIT_SAMPLE_DISABLE;
  huart3.Init.ClockPrescaler = UART_PRESCALER_DIV1;
  huart3.AdvancedInit.AdvFeatureInit = UART_ADVFEATURE_NO_INIT;
  if (HAL_UART_Init(&huart3) != HAL_OK)
  {
    Error_Handler();
  }
  if (HAL_UARTEx_SetTxFifoThreshold(&huart3, UART_TXFIFO_THRESHOLD_1_8) != HAL_OK)
  {
    Error_Handler();
  }
  if (HAL_UARTEx_SetRxFifoThreshold(&huart3, UART_RXFIFO_THRESHOLD_1_8) != HAL_OK)
  {
    Error_Handler();
  }
  if (HAL_UARTEx_DisableFifoMode(&huart3) != HAL_OK)
  {
    Error_Handler();
  }

}

static void MX_USART6_UART_Init(void)
{

  huart6.Instance = USART6;
  huart6.Init.BaudRate = 115200;
  huart6.Init.WordLength = UART_WORDLENGTH_8B;
  huart6.Init.StopBits = UART_STOPBITS_1;
  huart6.Init.Parity = UART_PARITY_NONE;
  huart6.Init.Mode = UART_MODE_TX_RX;
  huart6.Init.HwFlowCtl = UART_HWCONTROL_NONE;
  huart6.Init.OverSampling = UART_OVERSAMPLING_16;
  huart6.Init.OneBitSampling = UART_ONE_BIT_SAMPLE_DISABLE;
  huart6.Init.ClockPrescaler = UART_PRESCALER_DIV1;
  huart6.AdvancedInit.AdvFeatureInit = UART_ADVFEATURE_NO_INIT;
  if (HAL_UART_Init(&huart6) != HAL_OK)
  {
    Error_Handler();
  }
  if (HAL_UARTEx_SetTxFifoThreshold(&huart6, UART_TXFIFO_THRESHOLD_1_8) != HAL_OK)
  {
    Error_Handler();
  }
  if (HAL_UARTEx_SetRxFifoThreshold(&huart6, UART_RXFIFO_THRESHOLD_1_8) != HAL_OK)
  {
    Error_Handler();
  }
  if (HAL_UARTEx_DisableFifoMode(&huart6) != HAL_OK)
  {
    Error_Handler();
  }

}

static void MX_USB_OTG_HS_PCD_Init(void)
{

  hpcd_USB_OTG_HS.Instance = USB_OTG_HS;
  hpcd_USB_OTG_HS.Init.dev_endpoints = 9;
  hpcd_USB_OTG_HS.Init.speed = PCD_SPEED_HIGH;
  hpcd_USB_OTG_HS.Init.phy_itface = USB_OTG_HS_EMBEDDED_PHY;
  hpcd_USB_OTG_HS.Init.Sof_enable = DISABLE;
  hpcd_USB_OTG_HS.Init.low_power_enable = DISABLE;
  hpcd_USB_OTG_HS.Init.lpm_enable = DISABLE;
  hpcd_USB_OTG_HS.Init.use_dedicated_ep1 = DISABLE;
  hpcd_USB_OTG_HS.Init.vbus_sensing_enable = DISABLE;
  hpcd_USB_OTG_HS.Init.dma_enable = DISABLE;
  if (HAL_PCD_Init(&hpcd_USB_OTG_HS) != HAL_OK)
  {
    Error_Handler();
  }

}

static void MX_GPIO_Init(void)
{
  GPIO_InitTypeDef GPIO_InitStruct = {0};

  /* GPIO Ports Clock Enable */
  __HAL_RCC_GPIOE_CLK_ENABLE();
  __HAL_RCC_GPIOC_CLK_ENABLE();
  __HAL_RCC_GPIOF_CLK_ENABLE();
  __HAL_RCC_GPIOH_CLK_ENABLE();
  __HAL_RCC_GPIOA_CLK_ENABLE();
  __HAL_RCC_GPIOB_CLK_ENABLE();
  __HAL_RCC_GPIOD_CLK_ENABLE();
  __HAL_RCC_GPIOI_CLK_ENABLE();
  __HAL_RCC_GPIOG_CLK_ENABLE();

  /*Configure GPIO pin Output Level */
  HAL_GPIO_WritePin(LCD_ON_GPIO_Port, LCD_ON_Pin, GPIO_PIN_SET);

  /*Configure GPIO pin Output Level */
  HAL_GPIO_WritePin(GPIOD, RED_LED_Pin|GREEN_LED_Pin, GPIO_PIN_RESET);

  /*Configure GPIO pin : LCD_ON_Pin */
  GPIO_InitStruct.Pin = LCD_ON_Pin;
  GPIO_InitStruct.Mode = GPIO_MODE_OUTPUT_PP;
  GPIO_InitStruct.Pull = GPIO_NOPULL;
  GPIO_InitStruct.Speed = GPIO_SPEED_FREQ_LOW;
  HAL_GPIO_Init(LCD_ON_GPIO_Port, &GPIO_InitStruct);

  /*Configure GPIO pin : TP_IRQ_Pin */
  GPIO_InitStruct.Pin = TP_IRQ_Pin;
  GPIO_InitStruct.Mode = GPIO_MODE_IT_RISING;
  GPIO_InitStruct.Pull = GPIO_NOPULL;
  HAL_GPIO_Init(TP_IRQ_GPIO_Port, &GPIO_InitStruct);

  /*Configure GPIO pin : USB_DETECT_Pin */
  GPIO_InitStruct.Pin = USB_DETECT_Pin;
  GPIO_InitStruct.Mode = GPIO_MODE_IT_RISING_FALLING;
  GPIO_InitStruct.Pull = GPIO_NOPULL;
  HAL_GPIO_Init(USB_DETECT_GPIO_Port, &GPIO_InitStruct);

  /*Configure GPIO pin : USB_FAULT_Pin */
  GPIO_InitStruct.Pin = USB_FAULT_Pin;
  GPIO_InitStruct.Mode = GPIO_MODE_IT_FALLING;
  GPIO_InitStruct.Pull = GPIO_PULLUP;
  HAL_GPIO_Init(USB_FAULT_GPIO_Port, &GPIO_InitStruct);

  /*Configure GPIO pins : RED_LED_Pin GREEN_LED_Pin */
  GPIO_InitStruct.Pin = RED_LED_Pin|GREEN_LED_Pin;
  GPIO_InitStruct.Mode = GPIO_MODE_OUTPUT_PP;
  GPIO_InitStruct.Pull = GPIO_NOPULL;
  GPIO_InitStruct.Speed = GPIO_SPEED_FREQ_LOW;
  HAL_GPIO_Init(GPIOD, &GPIO_InitStruct);

  /* EXTI interrupt init*/
  HAL_NVIC_SetPriority(EXTI1_IRQn, 0, 0);
  HAL_NVIC_EnableIRQ(EXTI1_IRQn);

  HAL_NVIC_SetPriority(EXTI4_IRQn, 0, 0);
  HAL_NVIC_EnableIRQ(EXTI4_IRQn);

  HAL_NVIC_SetPriority(EXTI5_IRQn, 0, 0);
  HAL_NVIC_EnableIRQ(EXTI5_IRQn);

}

/* V6/A1.5 - el latido del HAL, ahora desde el TIM17 (ver
 * Core/Src/stm32u5xx_hal_timebase_tim.c). El SysTick es de FreeRTOS. */
void HAL_TIM_PeriodElapsedCallback(TIM_HandleTypeDef *htim)
{
  if (htim->Instance == TIM17)
  {
    HAL_IncTick();
  }
}

void Error_Handler(void)
{
  __disable_irq();
  while (1)
  {
  }
}
